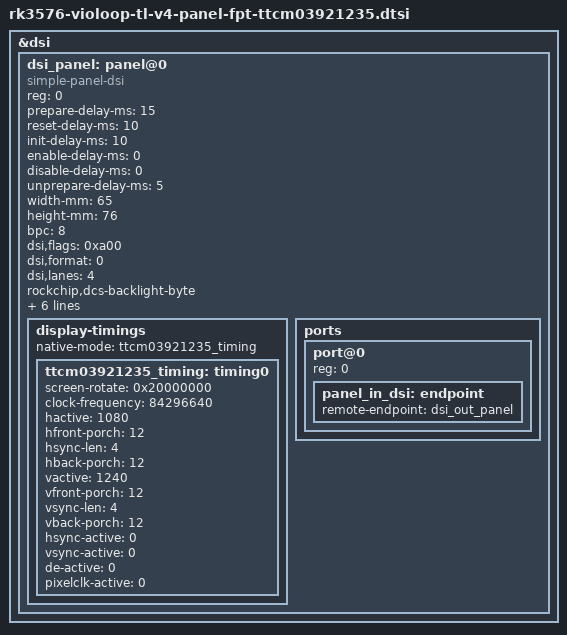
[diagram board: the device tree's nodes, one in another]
// SPDX-License-Identifier: (GPL-2.0+ OR MIT)
/*
 * FPT TTCM03921235 AMOLED module
 * Display controller: Chip Wealth CH13726A (factory programmed)
 * Touch controller: FocalTech FT3519 (described in the TL V4 base DTSI)
 *
 * The controller's OTP contains the vendor register configuration, so this
 * panel must not receive a full vendor initialization table.  It still needs
 * the supplier's short DCS wake sequence after reset: TE on, sleep out, then
 * display on with the specified delays.
 */

&dsi {
	dsi_panel: panel@0 {
		compatible = "simple-panel-dsi";
		reg = <0>;
		status = "okay";

		prepare-delay-ms = <15>;
		reset-delay-ms = <10>;
		init-delay-ms = <10>;
		enable-delay-ms = <0>;
		disable-delay-ms = <0>;
		unprepare-delay-ms = <5>;

		width-mm = <65>;
		height-mm = <76>;
		bpc = <8>;

		dsi,flags = <0xa00>;
		dsi,format = <0>;
		dsi,lanes = <4>;

		rockchip,dcs-backlight-byte;
		rockchip,dcs-backlight-max = <255>;
		rockchip,dcs-display-control;

		/* Supplier short code: 35 00; 11 + 120 ms; 29 + 40 ms. */
		panel-init-sequence = [
			15 00 02 35 00
			05 78 01 11
			05 28 01 29
		];
		panel-exit-sequence = [
			05 00 01 28
			05 78 01 10
		];

		display-timings {
			native-mode = <&ttcm03921235_timing>;

			ttcm03921235_timing: timing0 {
				/*
				 * U-Boot gets X mirror from vp1/xmirror-enable; supply the
				 * Y half here so its logo and Linux hand-off stay aligned.
				 * Linux ignores this U-Boot timing flag and mirrors VP1 X/Y.
				 */
				screen-rotate = <0x20000000>;
				clock-frequency = <84296640>;
				hactive = <1080>;
				hfront-porch = <12>;
				hsync-len = <4>;
				hback-porch = <12>;
				vactive = <1240>;
				vfront-porch = <12>;
				vsync-len = <4>;
				vback-porch = <12>;
				hsync-active = <0>;
				vsync-active = <0>;
				de-active = <0>;
				pixelclk-active = <0>;
			};
		};

		ports {
			#address-cells = <1>;
			#size-cells = <0>;

			port@0 {
				reg = <0>;

				panel_in_dsi: endpoint {
					remote-endpoint = <&dsi_out_panel>;
				};
			};
		};
	};
};
